# ATSAMA5D27 register map
Vendor: Microchip Technology Inc.; File version: 1.0
CPU: CA5 r0p1, little endian, no MPU, no FPU, 4 interrupt priority bits
Address unit: 32 bits
Registers are 32-bit, read-write, reset 0x0 unless marked. A register's access mark holds for its fields unless they carry their own. Offsets are from the block's base; [hi:lo] are bit positions; {n}, {i} and the like mark numbered series; 'fields as' and 'values as' point back to an identical list.

## SPIO — Parallel Input/Output Controller.
Base 0xFC039000
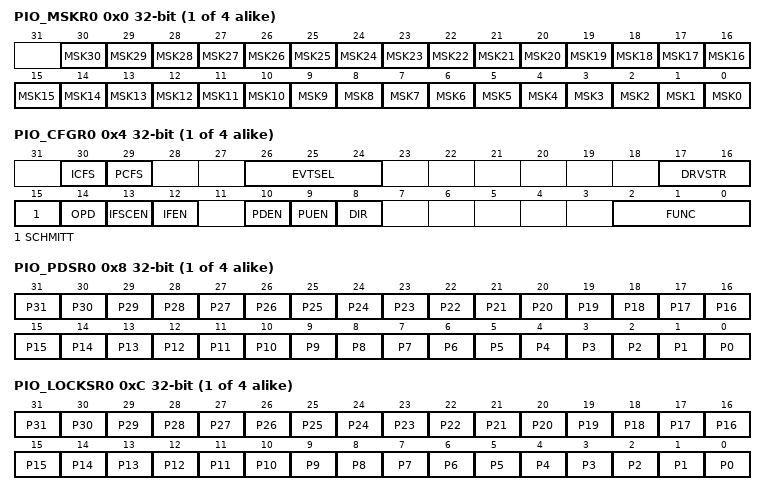
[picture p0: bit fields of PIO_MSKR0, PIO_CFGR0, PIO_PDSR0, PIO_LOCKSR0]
{0x0+0x40*i} PIO_MSKR{i} (i=0..3) — PIO Mask Register.
  [n] MSK{n} (n=0..30) — Selects the I/O line {n} to be configured when writing the PIO Configuration Register.
{0x4+0x40*i} PIO_CFGR{i} (i=0..3) — PIO Configuration Register.
  [30] ICFS ro — Interrupt Configuration Freeze Status.
  [29] PCFS ro — Physical Configuration Freeze Status.
  [26:24] EVTSEL — Event Selection.
    0=FALLING (Event detection on input falling edge.); 1=RISING (Event detection on input rising edge.); 2=BOTH (Event detection on input both edge.); 3=LOW (Event detection on low level input.); 4=HIGH (Event detection on high level input.)
  [17:16] DRVSTR — Drive Strength.
    0=LO0 (Low drive.); 1=LO1 (Low drive.); 2=ME (Medium drive.); 3=HI (Medium drive.)
  [15] SCHMITT — Schmitt Trigger.
    0=ENABLED (Schmitt trigger is enabled for the selected I/O lines.); 1=DISABLED (Schmitt trigger is disabled for the selected I/O lines.)
  [14] OPD — Open Drain.
    0=DISABLED (Open drain is disabled for the selected I/O lines.); 1=ENABLED (Open drain is enabled for the selected I/O lines.)
  [13] IFSCEN — Input Filter Slow Clock Enable.
    0=DISABLED (The input filter is disabled for the selected I/O lines.); 1=ENABLED (The input filter is enabled for the selected I/O lines.)
  [12] IFEN — Input Filter Enable.
    values as IFSCEN
  [10] PDEN — Pull-Down Enable.
    0=DISABLED (Pull-Up is disabled for the selected I/O lines.); 1=ENABLED (Pull-Up is enabled for the selected I/O lines.)
  [9] PUEN — Pull-Up Enable.
    values as PDEN
  [8] DIR — Direction.
    0=INPUT (The selected I/O lines are pure inputs.); 1=OUTPUT (The selected I/O lines are enabled in output.)
  [2:0] FUNC — I/O Line Function.
    0=GPIO (Selects GPIO mode for the selected I/O lines.); 1=PERIPH_A (Selects peripheral A for the selected I/O lines.); 2=PERIPH_B (Selects peripheral B for the selected I/O lines.); 3=PERIPH_C (Selects peripheral C for the selected I/O lines.); 4=PERIPH_D (Selects peripheral D for the selected I/O lines.); 5=PERIPH_E (Selects peripheral E for the selected I/O lines.); 6=PERIPH_F (Selects peripheral F for the selected I/O lines.)
{0x8+0x40*i} PIO_PDSR{i} (i=0..3) — PIO Pin Data Status Register.
  [n] P{n} (n=0..31) — The input data status of the I/O line {n}.
{0xC+0x40*i} PIO_LOCKSR{i} (i=0..3) — PIO Lock Status Register.
  [n] P{n} (n=0..31) — The lock status status of the I/O line {n}.
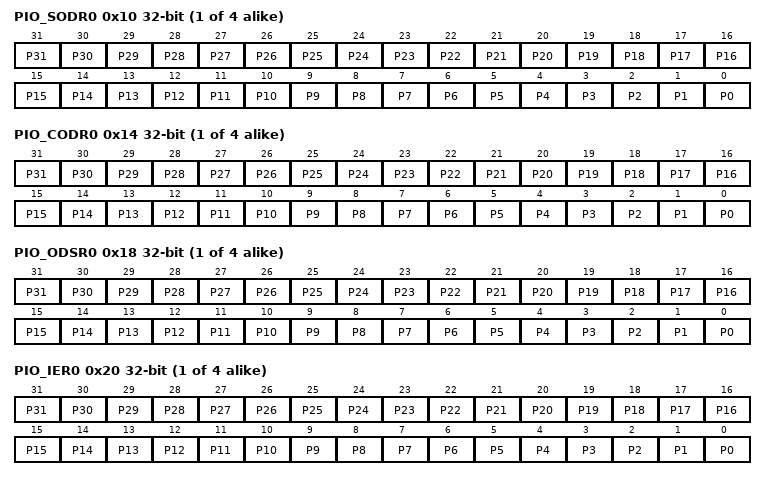
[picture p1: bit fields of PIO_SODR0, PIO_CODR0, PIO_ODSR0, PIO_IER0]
{0x10+0x40*i} PIO_SODR{i} (i=0..3) — PIO Set Output Data Register
  [n] P{n} (n=0..31) — Set the output data to be driven on the I/O line {n}.
{0x14+0x40*i} PIO_CODR{i} (i=0..3) — PIO Clear Output Data Register.
  [n] P{n} (n=0..31) — Clear the output data to be driven on the I/O line {n}.
{0x18+0x40*i} PIO_ODSR{i} (i=0..3) — PIO Output Data Status Register.
  [n] P{n} (n=0..31) — The output data status to be driven on the I/O line {n}.
{0x20+0x40*i} PIO_IER{i} wo (i=0..3) — PIO Interrupt Enable Register.
  [n] P{n} (n=0..31) — Enables the Input Change interrupt on the I/O line {n}.
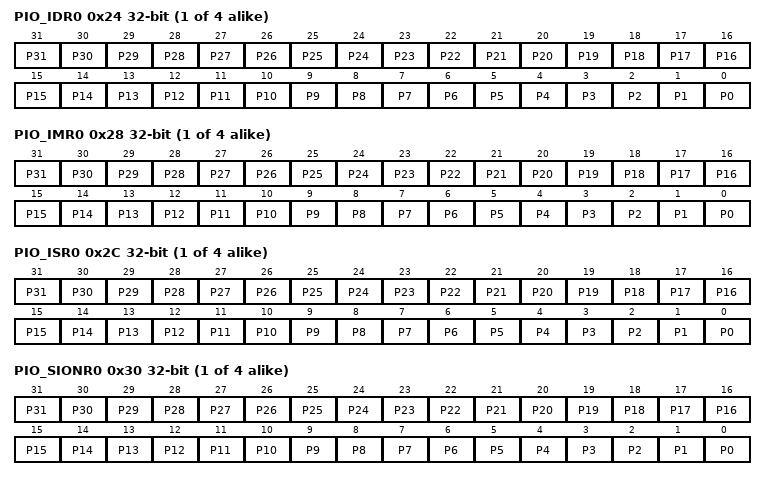
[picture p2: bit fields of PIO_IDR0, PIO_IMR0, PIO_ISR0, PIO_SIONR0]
{0x24+0x40*i} PIO_IDR{i} wo (i=0..3) — PIO Interrupt Disable Register.
  [n] P{n} (n=0..31) — Disables the Input Change interrupt on the I/O line {n}.
{0x28+0x40*i} PIO_IMR{i} ro (i=0..3) — PIO Interrupt Mask Register.
  [n] P{n} (n=0..31) — Input Change interrupt mask on the I/O line {n}.
{0x2C+0x40*i} PIO_ISR{i} ro (i=0..3) — PIO Interrupt Status Register
  [n] P{n} (n=0..31) — Input Change interrupt status on the I/O line {n}.
{0x30+0x40*i} PIO_SIONR{i} wo (i=0..3) — PIO Set I/O Non-Secure Register
  [n] P{n} (n=0..31) — Set the I/O line {n} in Non-Secure mode.
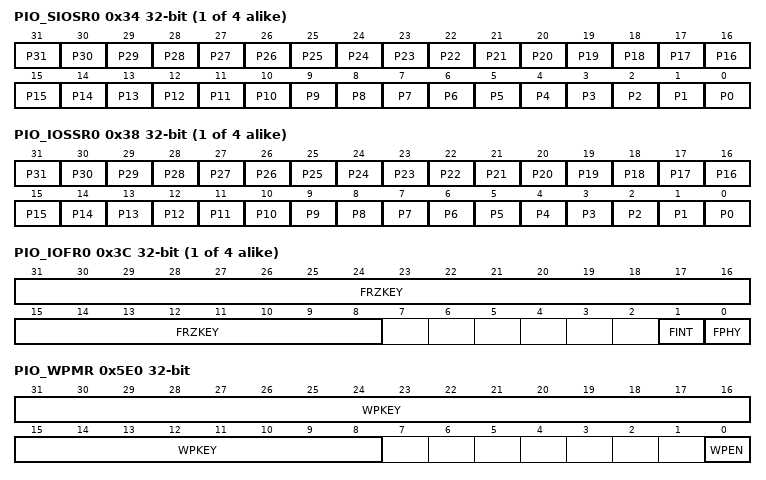
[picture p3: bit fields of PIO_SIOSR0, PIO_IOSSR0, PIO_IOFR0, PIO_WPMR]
{0x34+0x40*i} PIO_SIOSR{i} wo (i=0..3) — PIO Set I/O Secure Register
  [n] P{n} (n=0..31) — Set the I/O line {n} in Secure mode.
{0x38+0x40*i} PIO_IOSSR{i} ro (i=0..3) — PIO Set I/O Secure Register
  [n] P{n} (n=0..31) — I/O line {n} security status.
{0x3C+0x40*i} PIO_IOFR{i} wo (i=0..3) — PIO Freeze Configuration Register.
  [31:8] FRZKEY — Freeze Key.
    0x494F46=PASSWD (Freeze key.)
  [1] FINT — Freeze Interrupt Configuration.
    0=NONE (No effect.); 1=FREEZE (Freezes the following configuration of Non-Secure I/O lines if FRZKEY corresponds to 0x494F46, ("IOF" in ASCII): IFEN, IFSCEN and EVTSEL.)
  [0] FPHY — Freeze Physical Configuration.
    0=NONE (No effect.); 1=FREEZE (Freezes the following configuration of Non-Secure I/O lines if FRZKEY corresponds to 0x494F46, ("IOF" in ASCII): FUNC, DIR, PUEN, PDEN, OPD, SCHMITT and DRVSTR.)
0x500 PIO_SCDR — PIO Slow Clock Divider Debouncing Register
  [13:0] DIV — I/O Security Status.
0x5E0 PIO_WPMR wo — PIO Write Protection Mode Register.
  [31:8] WPKEY rw — Write Protection Key
    0x50494F=PASSWD (Writing any other value in this field aborts the write operation of the WPEN bit. Always reads as 0.)
  [0] WPEN rw — Write Protection Enable
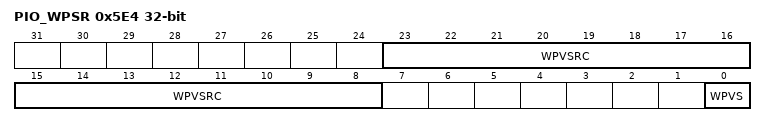
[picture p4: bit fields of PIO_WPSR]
0x5E4 PIO_WPSR ro — Write Protection Status Register.
  [23:8] WPVSRC rw — Write Protection Violation Source
  [0] WPVS rw — Write Protection Violation Status
